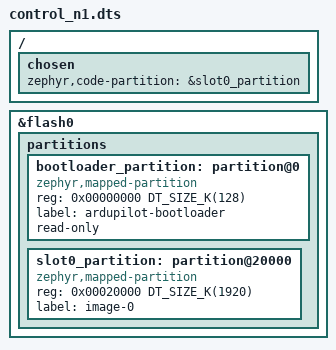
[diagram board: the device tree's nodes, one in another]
/*
 * SPDX-FileCopyrightText: Copyright The Zephyr Project Contributors
 * SPDX-License-Identifier: Apache-2.0
 */

/dts-v1/;
#include "control_n1_common.dtsi"

/ {
	chosen {
		zephyr,code-partition = &slot0_partition;
	};
};

/* The ArduPilot bootloader in the first sector loads the application after itself. */
&flash0 {
	partitions {
		ranges;
		#address-cells = <1>;
		#size-cells = <1>;

		bootloader_partition: partition@0 {
			compatible = "zephyr,mapped-partition";
			reg = <0x00000000 DT_SIZE_K(128)>;
			label = "ardupilot-bootloader";
			read-only;
		};

		slot0_partition: partition@20000 {
			compatible = "zephyr,mapped-partition";
			reg = <0x00020000 DT_SIZE_K(1920)>;
			label = "image-0";
		};
	};
};
